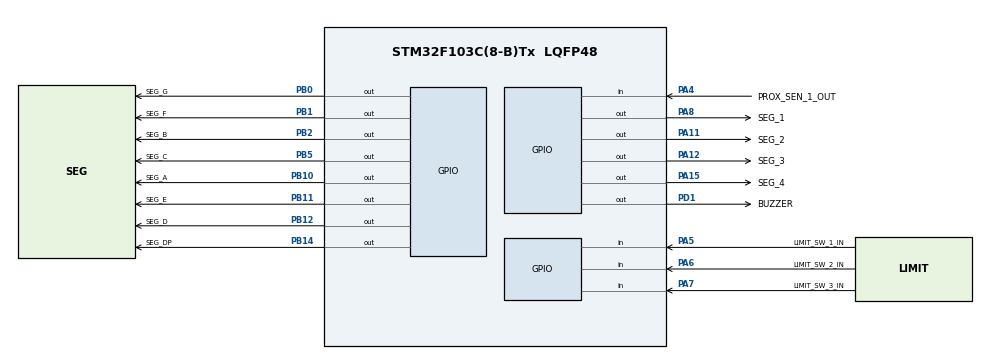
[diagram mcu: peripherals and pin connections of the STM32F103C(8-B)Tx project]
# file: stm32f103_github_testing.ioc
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Mcu.Family=STM32F1
Mcu.Name=STM32F103C(8-B)Tx
Mcu.Package=LQFP48
NVIC.PriorityGroup=NVIC_PRIORITYGROUP_4
NVIC.TIM2_IRQn=true\:0\:0\:false\:false\:true\:true\:true\:true
ProjectManager.HeapSize=0x200
ProjectManager.StackSize=0x400
ProjectManager.TargetToolchain=STM32CubeIDE
RCC.APB1Freq_Value=8000000
RCC.APB2Freq_Value=8000000
SYS.Debug=SYS_DEBUG_SERIAL_WIRE
TIM2.Period=0
TIM2.Prescaler=7999
VP_TIM2_VS_ClockSourceINT.Mode=Internal
PA4.GPIO_Label=PROX_SEN_1_OUT
PA4.GPIO_ModeDefaultInput=GPIO_MODE_INPUT
PA4.GPIO_PuPd=GPIO_NOPULL
PA4.Signal=GPIO_Input
PA5.GPIO_Label=LIMIT_SW_1_IN
PA5.GPIO_ModeDefaultInput=GPIO_MODE_INPUT
PA5.GPIO_PuPd=GPIO_NOPULL
PA5.Signal=GPIO_Input
PA6.GPIO_Label=LIMIT_SW_2_IN
PA6.GPIO_ModeDefaultInput=GPIO_MODE_INPUT
PA6.GPIO_PuPd=GPIO_NOPULL
PA6.Signal=GPIO_Input
PA7.GPIO_Label=LIMIT_SW_3_IN
PA7.GPIO_ModeDefaultInput=GPIO_MODE_INPUT
PA7.GPIO_PuPd=GPIO_NOPULL
PA7.Signal=GPIO_Input
PA8.GPIO_Label=SEG_1
PA8.GPIO_ModeDefaultOutputPP=GPIO_MODE_OUTPUT_PP
PA8.GPIO_PuPd=GPIO_NOPULL
PA8.GPIO_Speed=GPIO_SPEED_FREQ_LOW
PA8.PinState=GPIO_PIN_RESET
PA8.Signal=GPIO_Output
PA11.GPIO_Label=SEG_2
PA11.GPIO_ModeDefaultOutputPP=GPIO_MODE_OUTPUT_PP
PA11.GPIO_PuPd=GPIO_NOPULL
PA11.GPIO_Speed=GPIO_SPEED_FREQ_LOW
PA11.PinState=GPIO_PIN_RESET
PA11.Signal=GPIO_Output
PA12.GPIO_Label=SEG_3
PA12.GPIO_ModeDefaultOutputPP=GPIO_MODE_OUTPUT_PP
PA12.GPIO_PuPd=GPIO_NOPULL
PA12.GPIO_Speed=GPIO_SPEED_FREQ_LOW
PA12.PinState=GPIO_PIN_RESET
PA12.Signal=GPIO_Output
PA15.GPIO_Label=SEG_4
PA15.GPIO_ModeDefaultOutputPP=GPIO_MODE_OUTPUT_PP
PA15.GPIO_PuPd=GPIO_NOPULL
PA15.GPIO_Speed=GPIO_SPEED_FREQ_LOW
PA15.PinState=GPIO_PIN_RESET
PA15.Signal=GPIO_Output
PB0.GPIO_Label=SEG_G
PB0.GPIO_ModeDefaultOutputPP=GPIO_MODE_OUTPUT_PP
PB0.GPIO_PuPd=GPIO_NOPULL
PB0.GPIO_Speed=GPIO_SPEED_FREQ_LOW
PB0.PinState=GPIO_PIN_RESET
PB0.Signal=GPIO_Output
PB1.GPIO_Label=SEG_F
PB1.GPIO_ModeDefaultOutputPP=GPIO_MODE_OUTPUT_PP
PB1.GPIO_PuPd=GPIO_NOPULL
PB1.GPIO_Speed=GPIO_SPEED_FREQ_LOW
PB1.PinState=GPIO_PIN_RESET
PB1.Signal=GPIO_Output
PB2.GPIO_Label=SEG_B
PB2.GPIO_ModeDefaultOutputPP=GPIO_MODE_OUTPUT_PP
PB2.GPIO_PuPd=GPIO_NOPULL
PB2.GPIO_Speed=GPIO_SPEED_FREQ_LOW
PB2.PinState=GPIO_PIN_RESET
PB2.Signal=GPIO_Output
PB5.GPIO_Label=SEG_C
PB5.GPIO_ModeDefaultOutputPP=GPIO_MODE_OUTPUT_PP
PB5.GPIO_PuPd=GPIO_NOPULL
PB5.GPIO_Speed=GPIO_SPEED_FREQ_LOW
PB5.PinState=GPIO_PIN_RESET
PB5.Signal=GPIO_Output
PB10.GPIO_Label=SEG_A
PB10.GPIO_ModeDefaultOutputPP=GPIO_MODE_OUTPUT_PP
PB10.GPIO_PuPd=GPIO_NOPULL
PB10.GPIO_Speed=GPIO_SPEED_FREQ_LOW
PB10.PinState=GPIO_PIN_RESET
PB10.Signal=GPIO_Output
PB11.GPIO_Label=SEG_E
PB11.GPIO_ModeDefaultOutputPP=GPIO_MODE_OUTPUT_PP
PB11.GPIO_PuPd=GPIO_NOPULL
PB11.GPIO_Speed=GPIO_SPEED_FREQ_LOW
PB11.PinState=GPIO_PIN_RESET
PB11.PinState=GPIO_PIN_RESET
PB11.Signal=GPIO_Output
PB12.GPIO_Label=SEG_D
PB12.GPIO_ModeDefaultOutputPP=GPIO_MODE_OUTPUT_PP
PB12.GPIO_PuPd=GPIO_NOPULL
PB12.GPIO_Speed=GPIO_SPEED_FREQ_LOW
PB12.PinState=GPIO_PIN_RESET
PB12.Signal=GPIO_Output
PB14.GPIO_Label=SEG_DP
PB14.GPIO_ModeDefaultOutputPP=GPIO_MODE_OUTPUT_PP
PB14.GPIO_PuPd=GPIO_NOPULL
PB14.GPIO_Speed=GPIO_SPEED_FREQ_LOW
PB14.PinState=GPIO_PIN_RESET
PB14.Signal=GPIO_Output
PD1.GPIO_Label=BUZZER
PD1.GPIO_ModeDefaultOutputPP=GPIO_MODE_OUTPUT_PP
PD1.GPIO_PuPd=GPIO_NOPULL
PD1.GPIO_Speed=GPIO_SPEED_FREQ_LOW
PD1.PinState=GPIO_PIN_RESET
PD1.Signal=GPIO_Output
board=custom

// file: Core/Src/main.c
/* USER CODE BEGIN Header */
/**
  ******************************************************************************
  * @file           : main.c
  * @brief          : Main program body
  ******************************************************************************
  */
/* USER CODE END Header */

#include "main.h"

/* USER CODE BEGIN Includes */
#include "seven_seg.h"
#include "buzzer.h"
#include "proximity.h"
#include "limit_switch.h"
/* USER CODE END Includes */

TIM_HandleTypeDef htim2;

void SystemClock_Config(void);
static void MX_GPIO_Init(void);
static void MX_TIM2_Init(void);

/* USER CODE BEGIN 0 */
/* TIM2 generates a 1 ms interrupt for continuous 7-segment multiplexing. */
static uint16_t display_ms = 0U;
/* USER CODE END 0 */

int main(void)
{
  HAL_Init();

  SystemClock_Config();

  MX_GPIO_Init();
  MX_TIM2_Init();

  Buzzer_Init();
  SevenSeg_Init();
  SevenSeg_SetNumber(0U);

  if (HAL_TIM_Base_Start_IT(&htim2) != HAL_OK)
  {
    Error_Handler();
  }

  while (1)
  {
    /* Buzzer ON when proximity is detected AND any limit switch is pressed. */
    Buzzer_Update(Proximity_IsDetected(),
                  LimitSwitch_AnyPressed());
  }
}

void SystemClock_Config(void)
{
  RCC_OscInitTypeDef RCC_OscInitStruct = {0};
  RCC_ClkInitTypeDef RCC_ClkInitStruct = {0};

  RCC_OscInitStruct.OscillatorType = RCC_OSCILLATORTYPE_HSI;
  RCC_OscInitStruct.HSIState = RCC_HSI_ON;
  RCC_OscInitStruct.HSICalibrationValue = RCC_HSICALIBRATION_DEFAULT;
  RCC_OscInitStruct.PLL.PLLState = RCC_PLL_NONE;

  if (HAL_RCC_OscConfig(&RCC_OscInitStruct) != HAL_OK)
  {
    Error_Handler();
  }

  RCC_ClkInitStruct.ClockType = RCC_CLOCKTYPE_HCLK |
                                 RCC_CLOCKTYPE_SYSCLK |
                                 RCC_CLOCKTYPE_PCLK1 |
                                 RCC_CLOCKTYPE_PCLK2;
  RCC_ClkInitStruct.SYSCLKSource = RCC_SYSCLKSOURCE_HSI;
  RCC_ClkInitStruct.AHBCLKDivider = RCC_SYSCLK_DIV1;
  RCC_ClkInitStruct.APB1CLKDivider = RCC_HCLK_DIV1;
  RCC_ClkInitStruct.APB2CLKDivider = RCC_HCLK_DIV1;

  if (HAL_RCC_ClockConfig(&RCC_ClkInitStruct, FLASH_LATENCY_0) != HAL_OK)
  {
    Error_Handler();
  }
}

static void MX_TIM2_Init(void)
{
  TIM_ClockConfigTypeDef sClockSourceConfig = {0};

  htim2.Instance = TIM2;
  htim2.Init.Prescaler = 7999;
  htim2.Init.CounterMode = TIM_COUNTERMODE_UP;
  htim2.Init.Period = 0;
  htim2.Init.ClockDivision = TIM_CLOCKDIVISION_DIV1;
  htim2.Init.AutoReloadPreload = TIM_AUTORELOAD_PRELOAD_DISABLE;

  if (HAL_TIM_Base_Init(&htim2) != HAL_OK)
  {
    Error_Handler();
  }

  sClockSourceConfig.ClockSource = TIM_CLOCKSOURCE_INTERNAL;

  if (HAL_TIM_ConfigClockSource(&htim2, &sClockSourceConfig) != HAL_OK)
  {
    Error_Handler();
  }
}

static void MX_GPIO_Init(void)
{
  GPIO_InitTypeDef GPIO_InitStruct = {0};

  __HAL_RCC_GPIOA_CLK_ENABLE();
  __HAL_RCC_GPIOB_CLK_ENABLE();
  __HAL_RCC_GPIOD_CLK_ENABLE();

  /* All output pins start inactive. */
  HAL_GPIO_WritePin(GPIOD, GPIO_PIN_1, GPIO_PIN_RESET);
  HAL_GPIO_WritePin(GPIOA, GPIO_PIN_8 | GPIO_PIN_11 | GPIO_PIN_12 | GPIO_PIN_15,
                    GPIO_PIN_RESET);
  HAL_GPIO_WritePin(GPIOB, GPIO_PIN_0 | GPIO_PIN_1 | GPIO_PIN_2 |
                           GPIO_PIN_5 | GPIO_PIN_10 | GPIO_PIN_11 |
                           GPIO_PIN_12 | GPIO_PIN_14,
                    GPIO_PIN_RESET);

  /* PA4..PA7: proximity and limit switch inputs. */
  GPIO_InitStruct.Pin = GPIO_PIN_4 | GPIO_PIN_5 | GPIO_PIN_6 | GPIO_PIN_7;
  GPIO_InitStruct.Mode = GPIO_MODE_INPUT;
  GPIO_InitStruct.Pull = GPIO_NOPULL;
  HAL_GPIO_Init(GPIOA, &GPIO_InitStruct);

  /* PA8, PA11, PA12, PA15: 7-segment digit enables SEG1..SEG4. */
  GPIO_InitStruct.Pin = GPIO_PIN_8 | GPIO_PIN_11 | GPIO_PIN_12 | GPIO_PIN_15;
  GPIO_InitStruct.Mode = GPIO_MODE_OUTPUT_PP;
  GPIO_InitStruct.Pull = GPIO_NOPULL;
  GPIO_InitStruct.Speed = GPIO_SPEED_FREQ_LOW;
  HAL_GPIO_Init(GPIOA, &GPIO_InitStruct);

  /* PB0, PB1, PB2, PB5, PB10, PB11, PB12, PB14: 7-segment outputs. */
  GPIO_InitStruct.Pin = GPIO_PIN_0 | GPIO_PIN_1 | GPIO_PIN_2 |
                        GPIO_PIN_5 | GPIO_PIN_10 | GPIO_PIN_11 |
                        GPIO_PIN_12 | GPIO_PIN_14;
  GPIO_InitStruct.Mode = GPIO_MODE_OUTPUT_PP;
  GPIO_InitStruct.Pull = GPIO_NOPULL;
  GPIO_InitStruct.Speed = GPIO_SPEED_FREQ_LOW;
  HAL_GPIO_Init(GPIOB, &GPIO_InitStruct);

  /* PD1: buzzer. */
  GPIO_InitStruct.Pin = GPIO_PIN_1;
  GPIO_InitStruct.Mode = GPIO_MODE_OUTPUT_PP;
  GPIO_InitStruct.Pull = GPIO_NOPULL;
  GPIO_InitStruct.Speed = GPIO_SPEED_FREQ_LOW;
  HAL_GPIO_Init(GPIOD, &GPIO_InitStruct);
}

/* USER CODE BEGIN 4 */

void HAL_TIM_PeriodElapsedCallback(TIM_HandleTypeDef *htim)
{
  if (htim->Instance == TIM2)
  {
    /* Refresh one 7-segment digit every 1 ms. */
    SevenSeg_Tick();

    /* Update the displayed seconds exactly once every 1000 ms. */
    display_ms++;
    if (display_ms >= 1000U)
    {
      display_ms = 0U;
      SevenSeg_SecondTick();
    }
  }
}

/* USER CODE END 4 */

void Error_Handler(void)
{
  __disable_irq();

  while (1)
  {
  }
}
